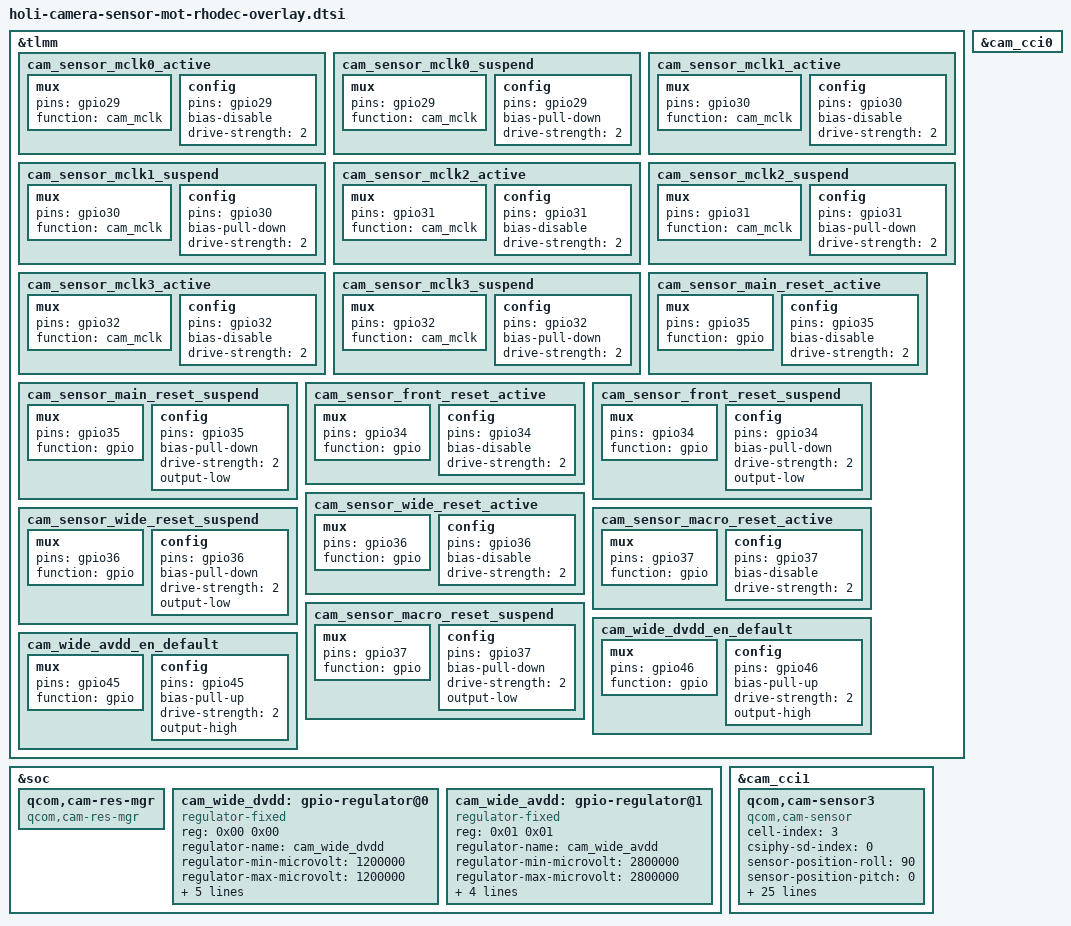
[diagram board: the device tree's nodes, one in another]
#include <dt-bindings/clock/qcom,gcc-holi.h>
#include <dt-bindings/msm/msm-camera.h>

&tlmm {
	cam_sensor_mclk0_active: cam_sensor_mclk0_active {
		mux {
			pins = "gpio29";
			function = "cam_mclk";
		};

		config {
			pins = "gpio29";
			bias-disable; /* No PULL */
			drive-strength = <2>; /* 2 MA */
		};
	};

	cam_sensor_mclk0_suspend: cam_sensor_mclk0_suspend {
		mux {
			pins = "gpio29";
			function = "cam_mclk";
		};

		config {
			pins = "gpio29";
			bias-pull-down; /* PULL DOWN */
			drive-strength = <2>; /* 2 MA */
		};
	};

	cam_sensor_mclk1_active: cam_sensor_mclk1_active {
		mux {
			pins = "gpio30";
			function = "cam_mclk";
		};

		config {
			pins = "gpio30";
			bias-disable; /* No PULL */
			drive-strength = <2>;
		};
	};

	cam_sensor_mclk1_suspend: cam_sensor_mclk1_suspend {
		mux {
			pins = "gpio30";
			function = "cam_mclk";
		};

		config {
			pins = "gpio30";
			bias-pull-down; /* PULL DOWN */
			drive-strength = <2>;
		};
	};

	cam_sensor_mclk2_active: cam_sensor_mclk2_active {
		mux {
			pins = "gpio31";
			function = "cam_mclk";
		};

		config {
			pins = "gpio31";
			bias-disable; /* No PULL */
			drive-strength = <2>;
		};
	};

	cam_sensor_mclk2_suspend: cam_sensor_mclk2_suspend {
		mux {
			pins = "gpio31";
			function = "cam_mclk";
		};

		config {
			pins = "gpio31";
			bias-pull-down; /* PULL DOWN */
			drive-strength = <2>;
		};
	};

	cam_sensor_mclk3_active: cam_sensor_mclk3_active {
		mux {
			pins = "gpio32";
			function = "cam_mclk";
		};

		config {
			pins = "gpio32";
			bias-disable; /* No PULL */
			drive-strength = <2>; /* 2 MA */
		};
	};

	cam_sensor_mclk3_suspend: cam_sensor_mclk3_suspend {
		mux {
			pins = "gpio32";
			function = "cam_mclk";
		};

		config {
			pins = "gpio32";
			bias-pull-down; /* PULL DOWN */
			drive-strength = <2>; /* 2 MA */
		};
	};

	cam_sensor_main_reset_active: cam_sensor_main_reset_active {
		mux {
			pins = "gpio35";
			function = "gpio";
		};

		config {
			pins = "gpio35";
			bias-disable; /* No PULL */
			drive-strength = <2>; /* 2 MA */
		};
	};

	cam_sensor_main_reset_suspend: cam_sensor_main_reset_suspend {
		mux {
			pins = "gpio35";
			function = "gpio";
		};

		config {
			pins = "gpio35";
			bias-pull-down; /* PULL DOWN */
			drive-strength = <2>; /* 2 MA */
			output-low;
		};
	};

	cam_sensor_front_reset_active: cam_sensor_front_reset_active {
		mux {
			pins = "gpio34";
			function = "gpio";
		};

		config {
			pins = "gpio34";
			bias-disable; /* No PULL */
			drive-strength = <2>; /* 2 MA */
		};
	};

	cam_sensor_front_reset_suspend: cam_sensor_front_reset_suspend {
		mux {
			pins = "gpio34";
			function = "gpio";
		};

		config {
			pins = "gpio34";
			bias-pull-down; /* PULL DOWN */
			drive-strength = <2>; /* 2 MA */
			output-low;
		};
	};

	cam_sensor_wide_reset_active: cam_sensor_wide_reset_active {
		mux {
			pins = "gpio36";
			function = "gpio";
		};

		config {
			pins = "gpio36";
			bias-disable; /* No PULL */
			drive-strength = <2>; /* 2 MA */
		};
	};

	cam_sensor_wide_reset_suspend: cam_sensor_wide_reset_suspend {
		mux {
			pins = "gpio36";
			function = "gpio";
		};

		config {
			pins = "gpio36";
			bias-pull-down; /* PULL DOWN */
			drive-strength = <2>; /* 2 MA */
			output-low;
		};
	};

	cam_sensor_macro_reset_active: cam_sensor_macro_reset_active {
		mux {
			pins = "gpio37";
			function = "gpio";
		};

		config {
			pins = "gpio37";
			bias-disable; /* No PULL */
			drive-strength = <2>; /* 2 MA */
		};
	};

	cam_sensor_macro_reset_suspend: cam_sensor_macro_reset_suspend {
		mux {
			pins = "gpio37";
			function = "gpio";
		};

		config {
			pins = "gpio37";
			bias-pull-down; /* PULL DOWN */
			drive-strength = <2>; /* 2 MA */
			output-low;
		};
	};

	cam_wide_dvdd_en_default: cam_wide_dvdd_en_default {
		mux {
			pins = "gpio46";
			function = "gpio";
		};

		config {
			pins = "gpio46";
			bias-pull-up; /* PULL UP */
			drive-strength = <2>; /* 2 MA */
			output-high;
		};
	};

	cam_wide_avdd_en_default: cam_wide_avdd_en_default {
		mux {
			pins = "gpio45";
			function = "gpio";
		};

		config {
			pins = "gpio45";
			bias-pull-up; /* PULL UP */
			drive-strength = <2>; /* 2 MA */
			output-high;
		};
	};
};

&soc {
	qcom,cam-res-mgr {
		compatible = "qcom,cam-res-mgr";
		status = "ok";
	};

	cam_wide_dvdd: gpio-regulator@0{
		compatible = "regulator-fixed";
		reg = <0x00 0x00>;
		regulator-name = "cam_wide_dvdd";
		regulator-min-microvolt = <1200000>;
		regulator-max-microvolt = <1200000>;
		regulator-enable-ramp-delay = <233>;
		enable-active-high;
		gpio = <&tlmm 46 0>;
		pinctrl-names = "default";
		pinctrl-0 = <&cam_wide_dvdd_en_default>;
		vin-supply = <&S6A>;
	};

	cam_wide_avdd: gpio-regulator@1{
		compatible = "regulator-fixed";
		reg = <0x01 0x01>;
		regulator-name = "cam_wide_avdd";
		regulator-min-microvolt = <2800000>;
		regulator-max-microvolt = <2800000>;
		regulator-enable-ramp-delay = <233>;
		enable-active-high;
		gpio = <&tlmm 45 0>;
		pinctrl-names = "default";
		pinctrl-0 = <&cam_wide_avdd_en_default>;
		/*vin-supply = <&BOB>;*/
	};
};

&cam_cci0 {

};

&cam_cci1 {
	qcom,cam-sensor3 {
		cell-index = <3>;
		compatible = "qcom,cam-sensor";
		csiphy-sd-index = <0>;
		sensor-position-roll = <90>;
		sensor-position-pitch = <0>;
		sensor-position-yaw = <180>;
		cam_vio-supply = <&L9A>;
		cam_vana-supply = <&cam_wide_avdd>;
		cam_vdig-supply = <&cam_wide_dvdd>;
		cam_clk-supply = <&gcc_camss_top_gdsc>;
		regulator-names = "cam_vio", "cam_vana", "cam_vdig",
			"cam_clk";
		rgltr-cntrl-support;
		rgltr-min-voltage = <1800000 2800000 1200000 0>;
		rgltr-max-voltage = <1800000 2800000 1200000 0>;
		rgltr-load-current = <120000 80000 1200000 0>;
		gpio-no-mux = <0>;
		pinctrl-names = "cam_default", "cam_suspend";
		pinctrl-0 = <&cam_sensor_mclk3_active
				&cam_sensor_wide_reset_active>;
		pinctrl-1 = <&cam_sensor_mclk3_suspend
				&cam_sensor_wide_reset_suspend>;
		gpios = <&tlmm 32 0>,
			<&tlmm 36 0>;
		gpio-reset = <1>;
		gpio-req-tbl-num = <0 1>;
		gpio-req-tbl-flags = <1 0>;
		gpio-req-tbl-label = "CAMIF_MCLK3",
					"CAM_RESET3";
		cci-master = <0>;
		status = "ok";
		clocks = <&gcc GCC_CAMSS_MCLK3_CLK>;
		clock-names = "cam_clk";
		clock-cntl-level = "turbo";
		clock-rates = <24000000>;
	};
};
